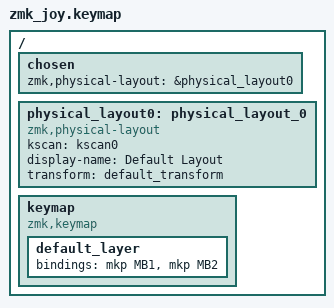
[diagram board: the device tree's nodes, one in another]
#include <behaviors.dtsi>
#include <dt-bindings/zmk/keys.h>
#include <dt-bindings/zmk/pointing.h>
#include <dt-bindings/zmk/bt.h>
#include <dt-bindings/zmk/outputs.h>
#include <physical_layouts.dtsi>

/ {

	chosen {
    zmk,physical-layout = &physical_layout0;
  };

	physical_layout0: physical_layout_0 {
		kscan = <&kscan0>;
        compatible = "zmk,physical-layout";
        display-name = "Default Layout";
		transform = <&default_transform>;
    };

    keymap {
        compatible = "zmk,keymap";

        default_layer {
            bindings = <
                &mkp MB1 &mkp MB2
            >;
        };
    };
};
